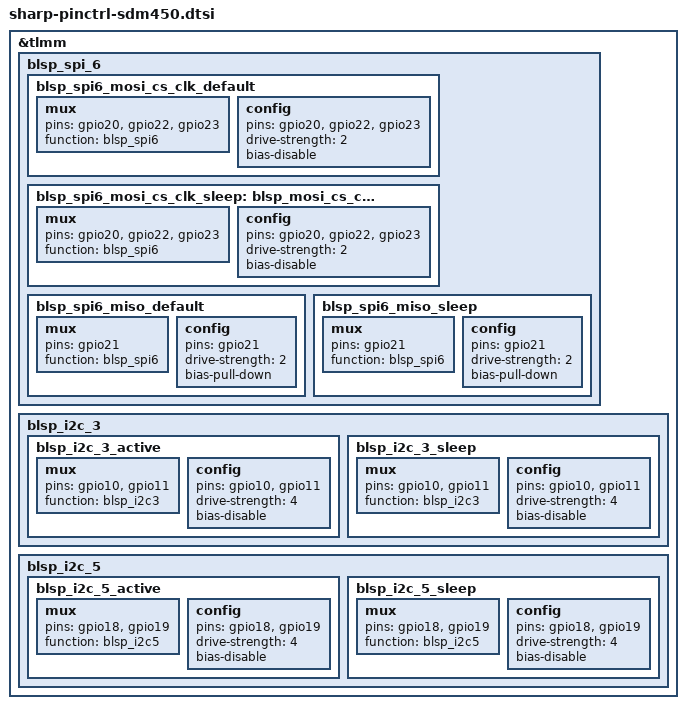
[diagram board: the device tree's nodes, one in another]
/*
 * Copyright (c) 2018, The Linux Foundation. All rights reserved.
 *
 * This program is free software; you can redistribute it and/or modify
 * it under the terms of the GNU General Public License version 2 and
 * only version 2 as published by the Free Software Foundation.
 *
 * This program is distributed in the hope that it will be useful,
 * but WITHOUT ANY WARRANTY; without even the implied warranty of
 * MERCHANTABILITY or FITNESS FOR A PARTICULAR PURPOSE.  See the
 * GNU General Public License for more details.
 */

/*****************************************/
/*  Add SHARP include                    */
/*****************************************/
#include "sharp-pinctrl-sdm450-nfc.dtsi"

&tlmm {
	/*------------------------------*/
	/*  UART/Serial                 */
	/*------------------------------*/


	/*------------------------------*/
	/*  SPI                         */
	/*------------------------------*/
	blsp_spi_6 {
		/* MOSI, CS, CLK */
		blsp_spi6_mosi_cs_clk_default: blsp_spi6_mosi_cs_clk_default {
			/* active state */
			mux {
				pins = "gpio20", "gpio22", "gpio23";
				function = "blsp_spi6";
			};

			config {
				pins = "gpio20", "gpio22", "gpio23";
				drive-strength = <2>;	/* 2 MA */
				bias-disable;			/* No PULL */
			};
		};

		/* MOSI, CS, CLK */
		blsp_spi6_mosi_cs_clk_sleep: blsp_mosi_cs_clk_spi6_sleep {
			/* suspended state */
			mux {
				pins = "gpio20", "gpio22", "gpio23";
				function = "blsp_spi6";
			};

			config {
				pins = "gpio20", "gpio22", "gpio23";
				drive-strength = <2>;	/* 2 MA */
				bias-disable;			/* No PULL */
			};
		};

		/* MISO */
		blsp_spi6_miso_default: blsp_spi6_miso_default {
			/* active state */
			mux {
				pins = "gpio21";
				function = "blsp_spi6";
			};

			config {
				pins = "gpio21";
				drive-strength = <2>;	/* 2 MA */
				bias-pull-down;			/* PULL Down */
			};
		};

		/* MISO */
		blsp_spi6_miso_sleep: blsp_spi6_miso_sleep {
			/* suspended state */
			mux {
				pins = "gpio21";
				function = "blsp_spi6";
			};

			config {
				pins = "gpio21";
				drive-strength = <2>;	/* 2 MA */
				bias-pull-down;			/* PULL Down */
			};
		};
	};

	/*------------------------------*/
	/*  I2C                         */
	/*------------------------------*/
	blsp_i2c_3 {
		blsp_i2c_3_active: blsp_i2c_3_active {
			/* active state */
			mux {
				pins = "gpio10", "gpio11";
				function = "blsp_i2c3";
			};

			config {
				pins = "gpio10", "gpio11";
				drive-strength = <4>;	/* 4 MA */
				bias-disable;			/* No PULL */
			};
		};

		blsp_i2c_3_sleep: blsp_i2c_3_sleep {
			/* suspended state */
			mux {
				pins = "gpio10", "gpio11";
				function = "blsp_i2c3";
			};

			config {
				pins = "gpio10", "gpio11";
				drive-strength = <4>;	/* 4 MA */
				bias-disable;			/* No PULL */
			};
		};
	};


	blsp_i2c_5 {
		blsp_i2c_5_active: blsp_i2c_5_active {
			/* active state */
			mux {
				pins = "gpio18", "gpio19";
				function = "blsp_i2c5";
			};

			config {
				pins = "gpio18", "gpio19";
				drive-strength = <4>;	/* 4 MA */
				bias-disable;			/* No PULL */
			};
		};

		blsp_i2c_5_sleep: blsp_i2c_5_sleep {
			/* suspended state */
			mux {
				pins = "gpio18", "gpio19";
				function = "blsp_i2c5";
			};

			config {
				pins = "gpio18", "gpio19";
				drive-strength = <4>;	/* 4 MA */
				bias-disable;			/* No PULL */
			};
		};
	};
};

